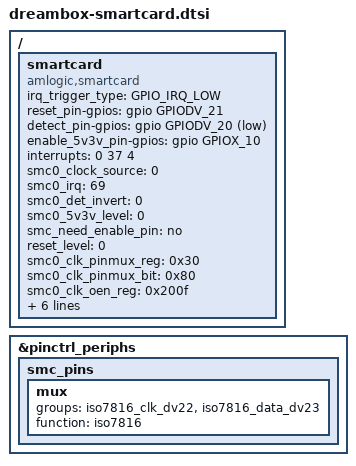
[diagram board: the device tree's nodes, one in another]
/*
 * arch/arm64/boot/dts/amlogic/dreambox-smartcard.dtsi
 *
 * Copyright (C) 2017 Dream Property GmbH. All rights reserved.
 *
 * This program is free software; you can redistribute it and/or modify
 * it under the terms of the GNU General Public License as published by
 * the Free Software Foundation; either version 2 of the License, or
 * (at your option) any later version.
 *
 * This program is distributed in the hope that it will be useful, but WITHOUT
 * ANY WARRANTY; without even the implied warranty of MERCHANTABILITY or
 * FITNESS FOR A PARTICULAR PURPOSE.  See the GNU General Public License for
 * more details.
 *
 */

/ {
	smartcard {
		compatible = "amlogic,smartcard";
		irq_trigger_type = "GPIO_IRQ_LOW";

		reset_pin-gpios = <&gpio GPIODV_21 GPIO_ACTIVE_HIGH>;
		detect_pin-gpios = <&gpio GPIODV_20 GPIO_ACTIVE_LOW>;
		enable_5v3v_pin-gpios = <&gpio GPIOX_10 GPIO_ACTIVE_HIGH >;	//5V3V pin, can be ignored

		interrupts = <0 37 4 >;	//smc irq

		smc0_clock_source = <0 >;	//Smc clock source, if change this, you must adjust clk and divider in smartcard.c
		smc0_irq = <69 >;		//smc irq
		smc0_det_invert = <0 >;		//0: high voltage on detect pin indicates card in.
		smc0_5v3v_level = <0 >;
		smc_need_enable_pin = "no";	//Ordinarily, smartcard controller needs a enable pin.
		// if board controls smartcard directly, then we don 't need it.
		//smc0_enable_pin-gpios = <&gpio GPIODV_17 GPIO_ACTIVE_LOW>;
		//smc0_enable_level = <0>;
		reset_level = <0>;					//0: pull low reset pin to reset card

		smc0_clk_pinmux_reg = <0x30>;
		smc0_clk_pinmux_bit = <0x80>;
		smc0_clk_oen_reg = <0x200f>;
		smc0_clk_out_reg = <0x2010>;
		smc0_clk_bit = <0x2000>;
		smc0_clk_oebit = <0x2000000>;
		smc0_clk_oubit = <0x1000000>;

		pinctrl-names = "default";
		pinctrl-0 = <&smc_pins>;

		clocks = <&clkc CLKID_FIXED_PLL>;
		clock-names = "clk_pll_fixed";

		status = "okay";
	};
};

&pinctrl_periphs {
	smc_pins: smc_pins {
		mux {
			groups = "iso7816_clk_dv22",
				"iso7816_data_dv23";
			function = "iso7816";
		};
	};
};
